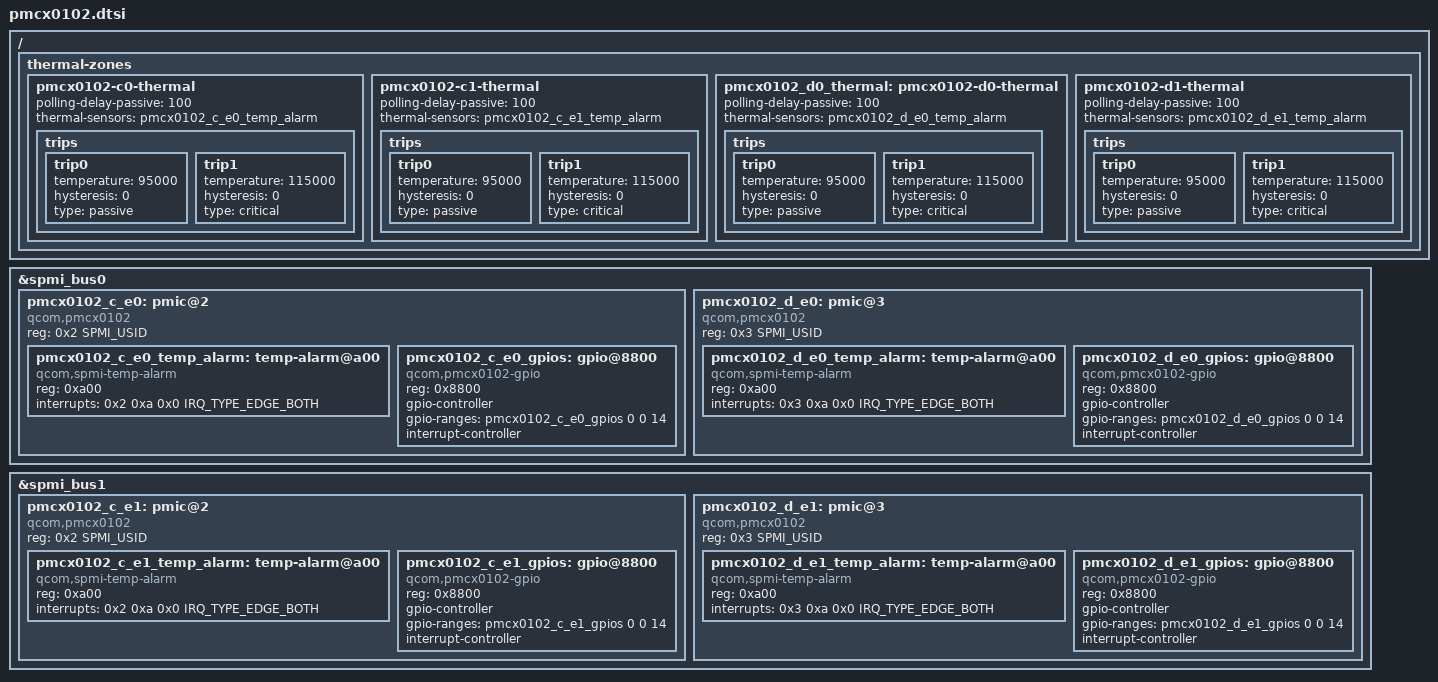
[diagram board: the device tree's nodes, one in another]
// SPDX-License-Identifier: BSD-3-Clause
/*
 * Copyright (c) Qualcomm Technologies, Inc. and/or its subsidiaries.
 */

#include <dt-bindings/interrupt-controller/irq.h>
#include <dt-bindings/spmi/spmi.h>

/ {
	thermal-zones {
		pmcx0102-c0-thermal {
			polling-delay-passive = <100>;
			thermal-sensors = <&pmcx0102_c_e0_temp_alarm>;

			trips {
				trip0 {
					temperature = <95000>;
					hysteresis = <0>;
					type = "passive";
				};

				trip1 {
					temperature = <115000>;
					hysteresis = <0>;
					type = "critical";
				};
			};
		};

		pmcx0102-c1-thermal {
			polling-delay-passive = <100>;
			thermal-sensors = <&pmcx0102_c_e1_temp_alarm>;

			trips {
				trip0 {
					temperature = <95000>;
					hysteresis = <0>;
					type = "passive";
				};

				trip1 {
					temperature = <115000>;
					hysteresis = <0>;
					type = "critical";
				};
			};
		};

		pmcx0102_d0_thermal: pmcx0102-d0-thermal {
			polling-delay-passive = <100>;
			thermal-sensors = <&pmcx0102_d_e0_temp_alarm>;

			trips {
				trip0 {
					temperature = <95000>;
					hysteresis = <0>;
					type = "passive";
				};

				trip1 {
					temperature = <115000>;
					hysteresis = <0>;
					type = "critical";
				};
			};
		};

		pmcx0102-d1-thermal {
			polling-delay-passive = <100>;
			thermal-sensors = <&pmcx0102_d_e1_temp_alarm>;

			trips {
				trip0 {
					temperature = <95000>;
					hysteresis = <0>;
					type = "passive";
				};

				trip1 {
					temperature = <115000>;
					hysteresis = <0>;
					type = "critical";
				};
			};
		};
	};
};

&spmi_bus0 {
	pmcx0102_c_e0: pmic@2 {
		compatible = "qcom,pmcx0102", "qcom,spmi-pmic";
		reg = <0x2 SPMI_USID>;
		#address-cells = <1>;
		#size-cells = <0>;

		pmcx0102_c_e0_temp_alarm: temp-alarm@a00 {
			compatible = "qcom,spmi-temp-alarm";
			reg = <0xa00>;
			interrupts = <0x2 0xa 0x0 IRQ_TYPE_EDGE_BOTH>;
			#thermal-sensor-cells = <0>;
		};

		pmcx0102_c_e0_gpios: gpio@8800 {
			compatible = "qcom,pmcx0102-gpio", "qcom,spmi-gpio";
			reg = <0x8800>;
			gpio-controller;
			gpio-ranges = <&pmcx0102_c_e0_gpios 0 0 14>;
			#gpio-cells = <2>;
			interrupt-controller;
			#interrupt-cells = <2>;
		};
	};

	pmcx0102_d_e0: pmic@3 {
		compatible = "qcom,pmcx0102", "qcom,spmi-pmic";
		reg = <0x3 SPMI_USID>;
		#address-cells = <1>;
		#size-cells = <0>;

		pmcx0102_d_e0_temp_alarm: temp-alarm@a00 {
			compatible = "qcom,spmi-temp-alarm";
			reg = <0xa00>;
			interrupts = <0x3 0xa 0x0 IRQ_TYPE_EDGE_BOTH>;
			#thermal-sensor-cells = <0>;
		};

		pmcx0102_d_e0_gpios: gpio@8800 {
			compatible = "qcom,pmcx0102-gpio", "qcom,spmi-gpio";
			reg = <0x8800>;
			gpio-controller;
			gpio-ranges = <&pmcx0102_d_e0_gpios 0 0 14>;
			#gpio-cells = <2>;
			interrupt-controller;
			#interrupt-cells = <2>;
		};
	};
};

&spmi_bus1 {
	pmcx0102_c_e1: pmic@2 {
		compatible = "qcom,pmcx0102", "qcom,spmi-pmic";
		reg = <0x2 SPMI_USID>;
		#address-cells = <1>;
		#size-cells = <0>;

		pmcx0102_c_e1_temp_alarm: temp-alarm@a00 {
			compatible = "qcom,spmi-temp-alarm";
			reg = <0xa00>;
			interrupts = <0x2 0xa 0x0 IRQ_TYPE_EDGE_BOTH>;
			#thermal-sensor-cells = <0>;
		};

		pmcx0102_c_e1_gpios: gpio@8800 {
			compatible = "qcom,pmcx0102-gpio", "qcom,spmi-gpio";
			reg = <0x8800>;
			gpio-controller;
			gpio-ranges = <&pmcx0102_c_e1_gpios 0 0 14>;
			#gpio-cells = <2>;
			interrupt-controller;
			#interrupt-cells = <2>;
		};
	};

	pmcx0102_d_e1: pmic@3 {
		compatible = "qcom,pmcx0102", "qcom,spmi-pmic";
		reg = <0x3 SPMI_USID>;
		#address-cells = <1>;
		#size-cells = <0>;

		pmcx0102_d_e1_temp_alarm: temp-alarm@a00 {
			compatible = "qcom,spmi-temp-alarm";
			reg = <0xa00>;
			interrupts = <0x3 0xa 0x0 IRQ_TYPE_EDGE_BOTH>;
			#thermal-sensor-cells = <0>;
		};

		pmcx0102_d_e1_gpios: gpio@8800 {
			compatible = "qcom,pmcx0102-gpio", "qcom,spmi-gpio";
			reg = <0x8800>;
			gpio-controller;
			gpio-ranges = <&pmcx0102_d_e1_gpios 0 0 14>;
			#gpio-cells = <2>;
			interrupt-controller;
			#interrupt-cells = <2>;
		};
	};
};
